# ATSAME51J19A device description
Architecture: CORTEX-M4; Family: SAME; Series: SAME51
Registers are 32-bit, read-write, reset 0x0 unless marked. A register's access mark holds for its fields unless they carry their own. Offsets are from the block's base; [hi:lo] are bit positions; {n}, {i} and the like mark numbered series; 'fields as' and 'values as' point back to an identical list.

## CAN_RXF1E — Rx FIFO 1 Element
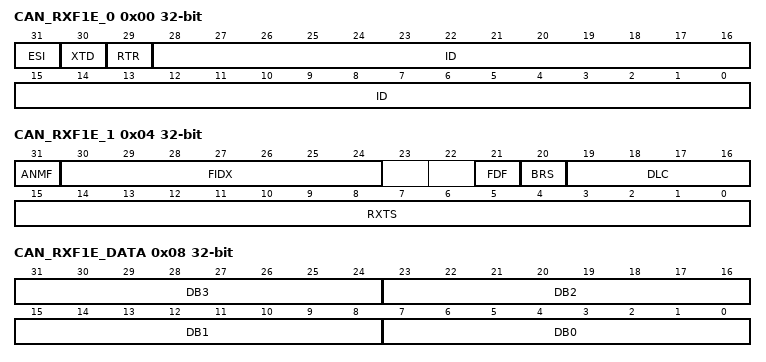
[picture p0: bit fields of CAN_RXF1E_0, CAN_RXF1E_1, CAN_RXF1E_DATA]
0x00 CAN_RXF1E_0 reset not defined — Rx FIFO 1 Element 0
  [31] ESI — Error State Indicator
  [30] XTD — Extended Identifier
  [29] RTR — Remote Transmission Request
  [28:0] ID — Identifier
0x04 CAN_RXF1E_1 reset not defined — Rx FIFO 1 Element 1
  [31] ANMF — Accepted Non-matching Frame
  [30:24] FIDX — Filter Index
  [21] FDF — FD Format
  [20] BRS — Bit Rate Switch
  [19:16] DLC — Data Length Code
  [15:0] RXTS — Rx Timestamp
0x08 CAN_RXF1E_DATA reset not defined — Rx FIFO 1 Element Data
  [8n+7:8n] DB{n} (n=0..3) — Data Byte {n}

## CAN_TXBE — Tx Buffer Element
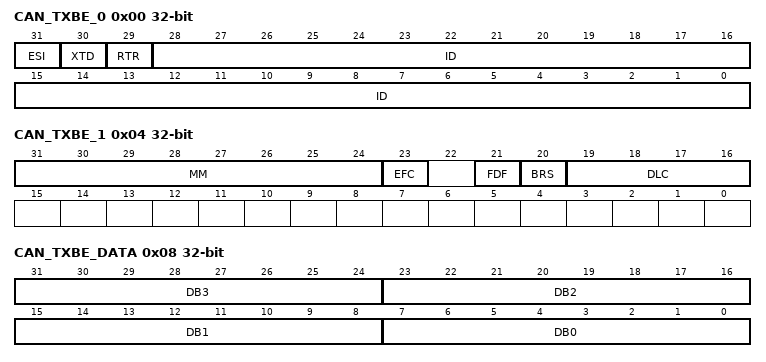
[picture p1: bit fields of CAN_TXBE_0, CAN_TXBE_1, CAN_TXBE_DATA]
0x00 CAN_TXBE_0 reset not defined — Tx Buffer Element 0
  [31] ESI — Error State Indicator
  [30] XTD — Extended Identifier
  [29] RTR — Remote Transmission Request
  [28:0] ID — Identifier
0x04 CAN_TXBE_1 reset not defined — Tx Buffer Element 1
  [31:24] MM — Message Marker
  [23] EFC — Event FIFO Control
  [21] FDF — FD Format
  [20] BRS — Bit Rate Switch
  [19:16] DLC — Data Length Code
0x08 CAN_TXBE_DATA reset not defined — Tx Buffer Element Data
  [8n+7:8n] DB{n} (n=0..3) — Data Byte {n}

## CAN_TXEFE — Tx Event FIFO Element
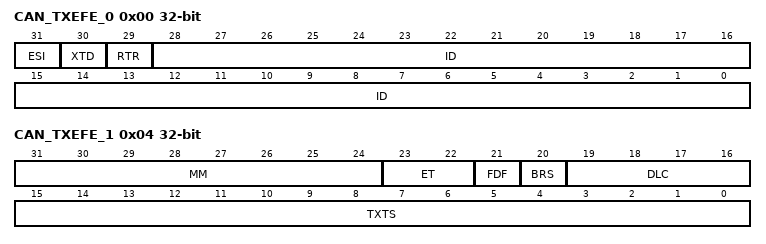
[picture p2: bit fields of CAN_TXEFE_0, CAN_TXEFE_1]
0x00 CAN_TXEFE_0 reset not defined — Tx Event FIFO Element 0
  [31] ESI — Error State Indicator
  [30] XTD — Extended Identifier
  [29] RTR — Remote Transmission Request
  [28:0] ID — Identifier
0x04 CAN_TXEFE_1 reset not defined — Tx Event FIFO Element 1
  [31:24] MM — Message Marker
  [23:22] ET — Event Type
    1=TXE (Tx event); 2=TXC (Transmission in spite of cancellation)
  [21] FDF — FD Format
  [20] BRS — Bit Rate Switch
  [19:16] DLC — Data Length Code
  [15:0] TXTS — Tx Timestamp

## CAN_SIDFE — Standard Message ID Filter Element
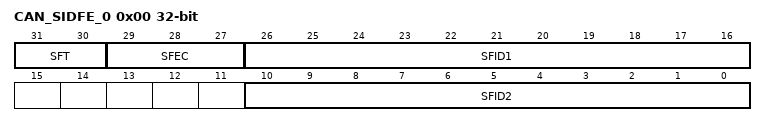
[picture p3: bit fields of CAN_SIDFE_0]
0x00 CAN_SIDFE_0 reset not defined — Standard Message ID Filter Element 0
  [31:30] SFT — Standard Filter Type
    0=RANGE (Range filter from SFID1 to SFID2); 1=DUAL (Dual ID filter for SFID1 or SFID2); 2=CLASSIC (Classic filter)
  [29:27] SFEC — Standard Filter Element Configuration
    0=DISABLE (Disable filter element); 1=STF0M (Store in Rx FIFO 0 if filter match); 2=STF1M (Store in Rx FIFO 1 if filter match); 3=REJECT (Reject ID if filter match); 4=PRIORITY (Set priority if filter match); 5=PRIF0M (Set priority and store in FIFO 0 if filter match); 6=PRIF1M (Set priority and store in FIFO 1 if filter match); 7=STRXBUF (Store into Rx Buffer)
  [26:16] SFID1 — Standard Filter ID 1
  [10:0] SFID2 — Standard Filter ID 2

## CAN_XIDFE — Extended Message ID Filter Element
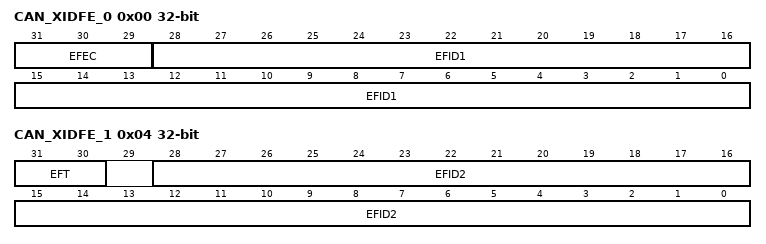
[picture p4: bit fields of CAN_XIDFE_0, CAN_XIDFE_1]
0x00 CAN_XIDFE_0 reset not defined — Extended Message ID Filter Element 0
  [31:29] EFEC — Extended Filter Element Configuration
    0=DISABLE (Disable filter element); 1=STF0M (Store in Rx FIFO 0 if filter match); 2=STF1M (Store in Rx FIFO 1 if filter match); 3=REJECT (Reject ID if filter match); 4=PRIORITY (Set priority if filter match); 5=PRIF0M (Set priority and store in FIFO 0 if filter match); 6=PRIF1M (Set priority and store in FIFO 1 if filter match); 7=STRXBUF (Store into Rx Buffer)
  [28:0] EFID1 — Extended Filter ID 1
0x04 CAN_XIDFE_1 reset not defined — Extended Message ID Filter Element 1
  [31:30] EFT — Extended Filter Type
    0=RANGEM (Range filter from EFID1 to EFID2); 1=DUAL (Dual ID filter for EFID1 or EFID2); 2=CLASSIC (Classic filter); 3=RANGE (Range filter from EFID1 to EFID2 with no XIDAM mask)
  [28:0] EFID2 — Extended Filter ID 2

## CCL — Configurable Custom Logic
Instances: CCL 0x42003800
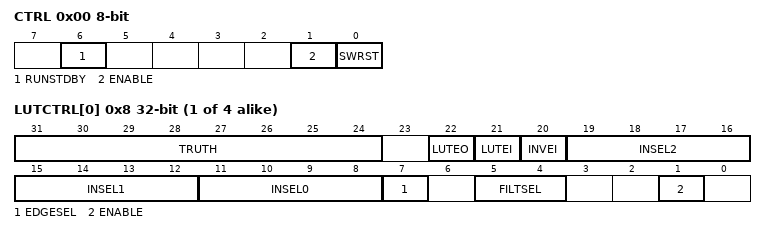
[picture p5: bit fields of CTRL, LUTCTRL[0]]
0x00 CTRL 8-bit — Control
  [6] RUNSTDBY — Run in Standby
    0=DISABLE (Generic clock is not required in standby sleep mode); 1=ENABLE (Generic clock is required in standby sleep mode)
  [1] ENABLE
    0=DISABLE (The peripheral is disabled); 1=ENABLE (The peripheral is enabled)
  [0] SWRST — Software Reset
    0=DISABLE (The peripheral is not reset); 1=ENABLE (The peripheral is reset)
{0x4+i} SEQCTRL[{i}] (i=0..1) 8-bit — SEQ Control x
  [3:0] SEQSEL — Sequential Selection
    0=DISABLE (Sequential logic is disabled); 1=DFF (D flip flop); 2=JK (JK flip flop); 3=LATCH (D latch); 4=RS (RS latch)
{0x8+4i} LUTCTRL[{i}] (i=0..3) — LUT Control x
  [31:24] TRUTH — Truth Value
  [22] LUTEO — LUT Event Output Enable
    0=DISABLE (LUT event output is disabled); 1=ENABLE (LUT event output is enabled)
  [21] LUTEI — LUT Event Input Enable
    0=DISABLE (LUT incoming event is disabled); 1=ENABLE (LUT incoming event is enabled)
  [20] INVEI — Inverted Event Input Enable
    0=DISABLE (Incoming event is not inverted); 1=ENABLE (Incoming event is inverted)
  [19:16] INSEL2 — Input Selection 2
    0=MASK (Masked input); 1=FEEDBACK (Feedback input source); 2=LINK (Linked LUT input source); 3=EVENT (Event input source); 4=IO (I/O pin input source); 5=AC (AC input source); 6=TC (TC input source); 7=ALTTC (Alternate TC input source); 8=TCC (TCC input source); 9=SERCOM (SERCOM input source)
  [15:12] INSEL1 — Input Selection 1
    values as INSEL2
  [11:8] INSEL0 — Input Selection 0
    values as INSEL2
  [7] EDGESEL — Edge Selection
    0=DISABLE (Edge detector is disabled); 1=ENABLE (Edge detector is enabled)
  [5:4] FILTSEL — Filter Selection
    0=DISABLE (Filter disabled); 1=SYNCH (Synchronizer enabled); 2=FILTER (Filter enabled)
  [1] ENABLE — LUT Enable
    0=DISABLE (LUT block is disabled); 1=ENABLE (LUT block is enabled)

## Notices in the file
Copyright (c) 2018 Microchip Technology Inc.
SPDX-License-Identifier: Apache-2.0
Licensed under the Apache License, Version 2.0 (the "License");
you may not use this file except in compliance with the License.
You may obtain a copy of the License at
http://www.apache.org/licenses/LICENSE-2.0
Unless required by applicable law or agreed to in writing, software
distributed under the License is distributed on an "AS IS" BASIS,
WITHOUT WARRANTIES OR CONDITIONS OF ANY KIND, either express or implied.
See the License for the specific language governing permissions and
limitations under the License.
